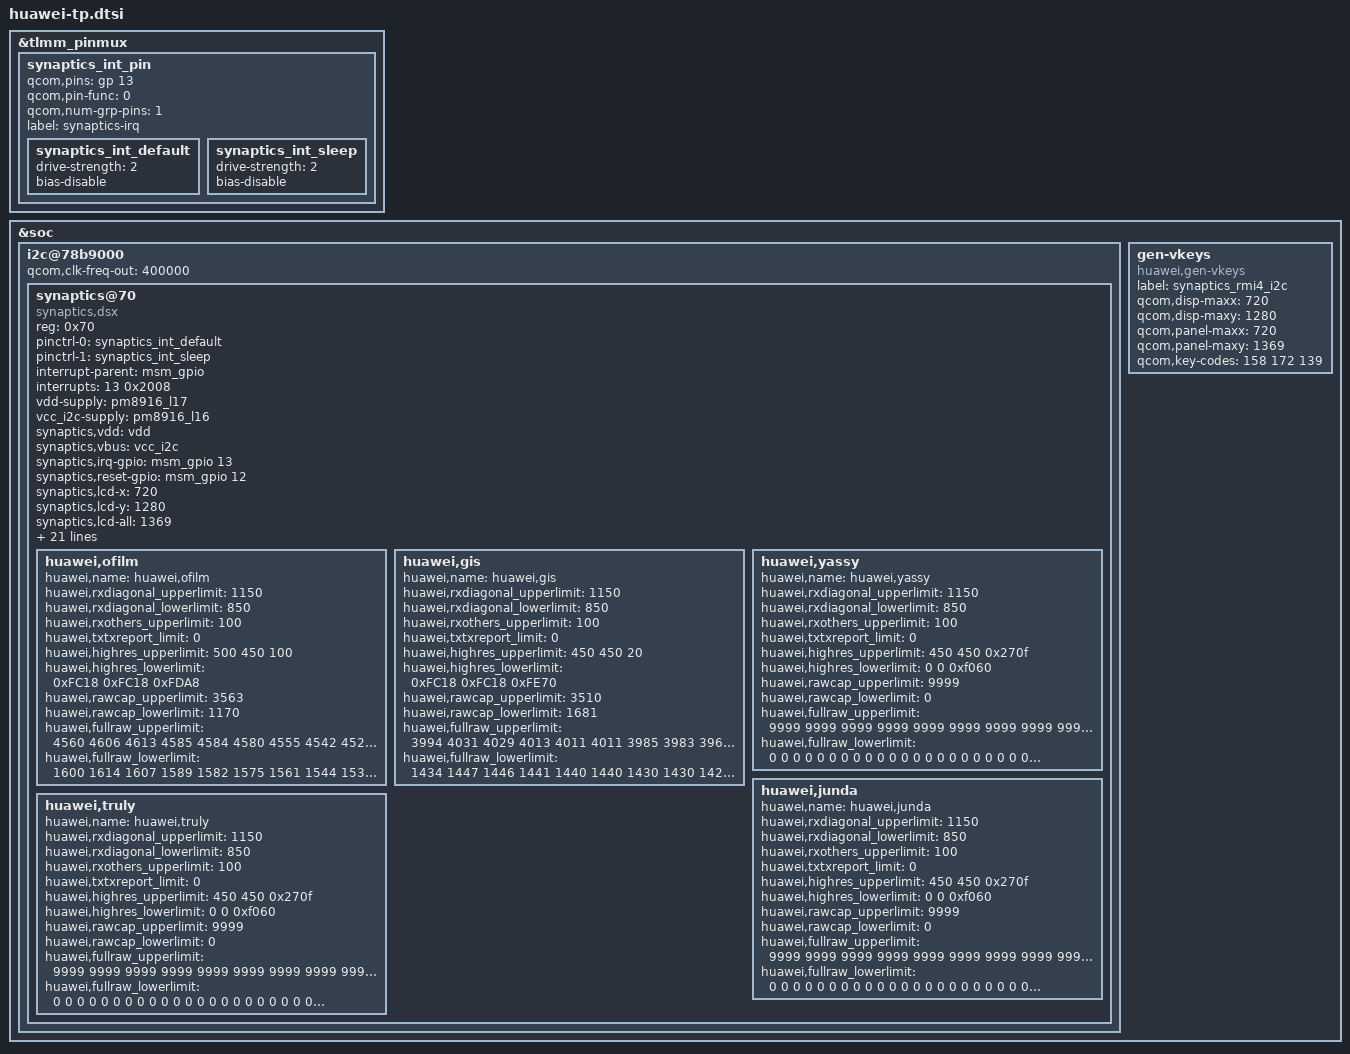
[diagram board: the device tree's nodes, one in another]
/*Add synaptics new driver "Synaptics DSX I2C V2.0"*/
/* Open holster flag */
&tlmm_pinmux {

	synaptics_int_pin {
		qcom,pins = <&gp 13>;
		qcom,pin-func = <0>;
		qcom,num-grp-pins = <1>;
		label = "synaptics-irq";
		synaptics_int_default: synaptics_int_default {
			drive-strength = <2>;
			bias-disable;
		};
		synaptics_int_sleep: synaptics_int_sleep {
			drive-strength = <2>;
			bias-disable;
		};
	};
};
&soc {
	i2c@78b9000 { /* BLSP1 QUP5 */
		status = "ok";
		#address-cells = <1>;
		#size-cells = <0>;
		qcom,clk-freq-out = <400000>;
		synaptics@70 {
			compatible = "synaptics,dsx";
			reg = <0x70>;
			pinctrl-names = "active","sleep";
			pinctrl-0 = <&synaptics_int_default>;
			pinctrl-1 = <&synaptics_int_sleep>;
			interrupt-parent = <&msm_gpio>;
			interrupts = <13 0x2008>;
			vdd-supply = <&pm8916_l17>;
			vcc_i2c-supply = <&pm8916_l16>;
			/* Some of qcom's param will not be replaced by huawei in dtb, */
			/* just ignore them:such as "pinctrl-names","pinctrl-0","pinctrl-1", */
			/* "synaptics,display-coords","synaptics,panel-coords","synaptics,i2c-pull-up", */
			/* "synaptics,power-down","synaptics,disable-gpios"*/
			synaptics,vdd = "vdd";
			synaptics,vbus = "vcc_i2c";
			synaptics,irq-gpio = <&msm_gpio 13 0x2008>;
			synaptics,reset-gpio = <&msm_gpio 12 0x0>;

			synaptics,lcd-x = <720>;
			synaptics,lcd-y = <1280>;
			synaptics,lcd-all = <1369>;
			synaptics,virtual_keys = /* KeyCode CenterX CenterY Width Height */
				/* KEY_BACK */
				<158 142 1342 150 100
				/* KEY_HOME(172) */
				172 360 1342 150 100
				/* KEY_MENU */
				139 578 1342 150 100>;

			/* SYNAPTICS_WAKE_UP_GESTURE_FLAG:'1'->enabled,'0'->disabled */
			/*IC flash is not enough for holster,so fw del one gesture*/
			synaptics,gesture_enabled = <0>;
			/* Gestures that supported:                           */
			/* bit0  Double tap                                        */
			/* bit1  Single finger slide from left to right     */
			/* bit2  Single finger slide from right to left     */
			/* bit3  Single finger slide from top to bottom  */
			/* bit4  Single finger slide from bottom to top  */
			/* bit5  Double finger slide from top to bottom--disable for holster*/
			/* bit6  Single finger slide circle                     */
			/* bit7  Single finger write letter c                  */
			/* bit8  Single finger write letter e                  */
			/* bit9  Single finger write letter m                 */
			/* bit10 Single finger write letter w                 */
			/* bit11 Palm off screen                                */
			synaptics,easy_wakeup_supported_gestures = <0xF81>;

			/*Defination of report key value  for different gestures*/
			synaptics,easy_wakeup_gesture_keys = 
			<	59 /*0.Double tap:KEY_F1*/
				60 /*1.Single finger slide from left to right*/
				61 /*2.Single finger slide from right to left:KEY_F3*/
				62 /*3.Single finger slide from top to bottom*/
				63 /*4.Single finger slide from bottom to top:KEY_F5*/
				64 /*5.Single finger slide circle clockwise*/
				65 /*6.Single finger slide circle counter-clockwise*/
				66 /*7.Single finger write letter c*/
				67 /*8.Single finger write letter e:KEY_F9*/
				68 /*9.Single finger write letter m*/
				87 /*10.Single finger write letter w:KEY_F11*/
				88 /*11.Palm off screen*/
			>;

			/* Double-tap-zone defined by huawei */
			/* Shielded area is:1cm left,1cm right,3cm up,2cm down */
			huawei,dtz_x0 = <104>;
			huawei,dtz_y0 = <423>;
			huawei,dtz_x1 = <616>;
			huawei,dtz_y1 = <1068>;

			/* SYNAPTICS_GLOVE_FUNCTION_FLAG:'1'->enabled,'0'->disabled*/
			synaptics,glove_enabled = <0>;
			/*After reduce power-consumption by exit reduce mode,*/
			/*we have to reduce f-r rate to make sure gesture work fine*/
			synaptics,fast_relax_gesture = <7>;
			/*Holster support flag*/
			synaptics,holster_supported = <1>;
			synaptics,esd_support = <1>;
			sybaptics,support_low_power_model = <0>;

			synaptics,reset-on-status = <0>;
			synaptics,power-delay-ms = <160>;
			synaptics,reset-delay-ms = <250>;
			synaptics,reset-active-ms = <10>;
			synaptics,product_name = "cherry";

			/*capacitance self-adapt*/
			/*To adjust the cutting angle threshold to the maximum range*/
			huawei,ofilm {
				huawei,name = "huawei,ofilm";
				huawei,rxdiagonal_upperlimit = <1150>;
				huawei,rxdiagonal_lowerlimit = <850>;
				huawei,rxothers_upperlimit = <100>;
				huawei,txtxreport_limit = <0>;
				huawei,highres_upperlimit = <500 450 100>;
				huawei,highres_lowerlimit = <0xFC18 0xFC18 0xFDA8>;
				huawei,rawcap_upperlimit = <3563>;
				huawei,rawcap_lowerlimit = <1170>;

				huawei,fullraw_upperlimit =
					<4560 4606 4613 4585 4584 4580 4555 4542 4527 4508 4491 4475 4448 4055 4026 4044 3985 4007 3958 3982 3931 3956 3907 3934 3791 3651
					 4416 4460 4442 4425 4404 4390 4374 4358 4342 4323 4308 4294 4263 4077 4044 4065 4011 4030 3986 4012 3964 3988 3941 3969 3827 3686
					 4402 4446 4425 4406 4386 4367 4349 4330 4312 4289 4274 4254 4225 4079 4051 4069 4015 4032 3991 4020 3969 3995 3948 3977 3838 3695
					 4398 4439 4420 4400 4376 4356 4336 4316 4297 4270 4255 4237 4207 4092 4066 4086 4032 4047 4005 4038 3986 4013 3968 3996 3857 3710
					 4380 4422 4399 4379 4355 4334 4312 4296 4271 4246 4228 4209 4178 4098 4075 4091 4042 4055 4016 4045 3994 4020 3979 4006 3868 3697
					 4368 4410 4384 4368 4341 4319 4294 4275 4254 4228 4211 4189 4155 4113 4089 4108 4059 4075 4032 4062 4016 4038 3998 4025 3888 3714
					 4362 4406 4381 4363 4335 4314 4289 4268 4248 4216 4203 4179 4143 4138 4110 4131 4086 4101 4060 4089 4046 4068 4028 4053 3919 3738
					 4353 4392 4370 4349 4323 4301 4277 4254 4231 4199 4185 4164 4127 4160 4134 4153 4108 4124 4080 4111 4070 4093 4052 4082 3944 3766
					 4337 4378 4353 4331 4307 4286 4260 4236 4216 4180 4167 4148 4107 4178 4155 4173 4129 4148 4103 4138 4094 4120 4081 4109 3968 3787
					 4337 4378 4351 4329 4301 4283 4255 4234 4212 4179 4165 4144 4105 4211 4190 4209 4165 4187 4145 4173 4131 4160 4123 4151 4011 3826
					 4325 4365 4339 4319 4292 4273 4246 4224 4201 4171 4155 4134 4092 4237 4218 4236 4199 4218 4181 4205 4167 4196 4162 4189 4046 3887
					 4320 4356 4335 4313 4286 4266 4241 4219 4193 4167 4151 4130 4087 4270 4251 4272 4237 4255 4220 4241 4211 4234 4202 4228 4086 3928
					 4321 4362 4336 4311 4288 4268 4244 4222 4198 4169 4153 4134 4090 4319 4302 4325 4291 4313 4283 4303 4272 4299 4263 4288 4148 3998
					 4314 4340 4316 4292 4265 4245 4218 4197 4168 4137 4120 4101 4051 4631 4590 4605 4541 4564 4538 4532 4507 4525 4483 4503 4357 4211>;

				huawei,fullraw_lowerlimit =
					<1600 1614 1607 1589 1582 1575 1561 1544 1530 1521 1509 1490 1479 1325 1301 1299 1283 1268 1230 1253 1238 1242 1218 1185 1180 1177 
					1555 1564 1551 1538 1525 1509 1501 1484 1470 1460 1449 1432 1423 1339 1316 1316 1267 1214 1213 1280 1256 1262 1218 1169 1191 1184 
					1548 1555 1544 1529 1518 1500 1491 1474 1458 1448 1435 1418 1405 1341 1318 1318 1214 1198 1174 1279 1261 1266 1240 1204 1224 1254 
					1543 1551 1533 1520 1509 1496 1484 1467 1453 1440 1421 1411 1397 1346 1325 1286 1198 1202 1178 1288 1264 1272 1250 1211 1252 1250 
					1536 1543 1530 1516 1502 1488 1478 1460 1444 1432 1416 1404 1389 1353 1333 1294 1208 1210 1231 1292 1275 1282 1257 1215 1262 1242 
					1533 1539 1526 1510 1496 1484 1471 1455 1439 1426 1411 1397 1378 1356 1337 1339 1299 1305 1288 1296 1278 1285 1264 1225 1267 1253 
					1527 1539 1519 1504 1490 1477 1465 1446 1429 1416 1400 1386 1365 1362 1341 1346 1321 1325 1297 1300 1283 1292 1269 1229 1273 1311 
					1524 1533 1517 1500 1484 1472 1460 1439 1425 1410 1395 1375 1355 1369 1348 1353 1327 1332 1306 1305 1292 1299 1281 1241 1279 1314 
					1519 1528 1512 1494 1478 1469 1451 1432 1420 1402 1387 1374 1354 1379 1361 1364 1342 1345 1316 1320 1302 1313 1291 1254 1293 1281 
					1519 1529 1512 1495 1480 1465 1450 1430 1415 1400 1383 1363 1344 1388 1369 1372 1348 1352 1328 1327 1314 1325 1304 1264 1299 1283 
					1514 1523 1505 1489 1475 1461 1447 1427 1411 1394 1378 1362 1341 1400 1379 1383 1360 1363 1341 1341 1323 1298 1288 1274 1310 1311 
					1512 1520 1503 1487 1471 1458 1443 1422 1407 1390 1375 1357 1334 1407 1388 1392 1370 1370 1350 1350 1291 1222 1213 1295 1320 1389 
					1511 1521 1503 1488 1471 1458 1441 1423 1404 1390 1371 1353 1328 1423 1400 1409 1386 1384 1367 1368 1304 1236 1225 1274 1336 1337 
					1516 1518 1502 1482 1464 1451 1432 1410 1395 1378 1358 1338 1313 1508 1490 1491 1457 1461 1433 1433 1418 1319 1290 1338 1379 1388>;
			};
			huawei,gis {
				huawei,name = "huawei,gis";
				huawei,rxdiagonal_upperlimit = <1150>;
				huawei,rxdiagonal_lowerlimit = <850>;
				huawei,rxothers_upperlimit = <100>;
				huawei,txtxreport_limit = <0>;
				huawei,highres_upperlimit = <450 450 20>;
				huawei,highres_lowerlimit = <0xFC18 0xFC18 0xFE70>;
				huawei,rawcap_upperlimit = <3510>;
				huawei,rawcap_lowerlimit = <1681>;

				huawei,fullraw_upperlimit =
					<3994 4031 4029 4013 4011 4011 3985 3983 3966 3957 3947 3942 4048 3531 3533 3520 3505 3494 3510 3487 3487 3472 3468 3450 3445 3279
					 4118 4151 4141 4118 4109 4105 4073 4068 4047 4034 4018 4011 3975 3790 3792 3778 3764 3754 3774 3751 3751 3738 3735 3715 3712 3583
					 4109 4141 4128 4104 4094 4087 4053 4050 4024 4011 3994 3982 3934 3790 3790 3775 3760 3753 3770 3748 3748 3735 3732 3713 3715 3868
					 4096 4130 4116 4091 4078 4072 4037 4030 4004 3988 3972 3962 3908 3797 3796 3783 3770 3761 3780 3757 3758 3744 3740 3723 3721 3645
					 4077 4116 4100 4076 4064 4056 4021 4013 3986 3972 3953 3946 3887 3808 3805 3792 3782 3773 3792 3770 3770 3757 3753 3734 3731 3565
					 4069 4107 4092 4068 4055 4047 4011 4003 3974 3959 3942 3931 3870 3823 3821 3808 3796 3788 3808 3784 3784 3771 3767 3751 3747 3595
					 4061 4098 4081 4056 4042 4034 3996 3988 3960 3944 3926 3916 3852 3840 3835 3822 3809 3803 3822 3799 3799 3784 3780 3764 3766 3862
					 4052 4087 4070 4044 4030 4024 3985 3977 3947 3933 3914 3904 3839 3865 3857 3844 3831 3823 3843 3819 3819 3805 3804 3783 3787 3866
					 4046 4079 4064 4038 4022 4016 3979 3969 3940 3926 3908 3899 3831 3888 3878 3866 3856 3847 3868 3847 3847 3834 3831 3813 3813 3676
					 4042 4077 4060 4034 4018 4011 3974 3965 3938 3923 3904 3894 3825 3917 3905 3895 3882 3874 3895 3873 3873 3861 3860 3843 3844 3708
					 4038 4073 4056 4029 4014 4005 3968 3960 3931 3918 3897 3887 3819 3946 3930 3921 3909 3900 3921 3900 3900 3888 3887 3874 3877 3826
					 4034 4070 4052 4026 4011 4003 3965 3959 3927 3914 3895 3886 3816 3973 3957 3947 3936 3927 3947 3926 3927 3917 3921 3907 3916 4157
					 4029 4065 4050 4024 4011 4003 3968 3960 3931 3918 3900 3891 3821 4029 4001 3992 3983 3973 3995 3977 3978 3970 3974 3961 3964 3905
					 3797 3821 3804 3777 3762 3752 3715 3705 3675 3662 3643 3632 3562 4563 4117 4079 4051 4031 4043 4018 4014 4004 4003 3990 3994 4120>;

				huawei,fullraw_lowerlimit =
					<1434 1447 1446 1441 1440 1440 1430 1430 1424 1420 1417 1415 1453 1268 1268 1264 1258 1254 1260 1252 1252 1247 1245 1239 1237 1177
					 1478 1490 1486 1478 1475 1474 1462 1460 1453 1448 1443 1440 1427 1360 1362 1356 1351 1348 1355 1346 1346 1342 1341 1334 1332 1286
					 1476 1486 1482 1474 1469 1467 1455 1453 1444 1439 1434 1429 1413 1360 1360 1355 1350 1347 1354 1345 1345 1341 1340 1333 1334 1280
					 1471 1483 1478 1469 1464 1462 1449 1447 1437 1432 1426 1422 1403 1363 1363 1358 1353 1350 1357 1349 1349 1344 1343 1337 1336 1308
					 1464 1477 1472 1463 1459 1456 1443 1441 1431 1426 1419 1416 1395 1367 1366 1362 1357 1354 1362 1353 1353 1349 1347 1341 1340 1280
					 1460 1474 1469 1460 1455 1453 1439 1436 1427 1421 1415 1411 1389 1373 1371 1367 1363 1359 1367 1359 1359 1354 1352 1346 1345 1290
					 1457 1471 1465 1456 1451 1448 1434 1432 1421 1416 1409 1406 1383 1379 1376 1372 1367 1365 1372 1364 1364 1359 1357 1351 1352 1386
					 1455 1467 1462 1452 1447 1444 1431 1427 1417 1412 1406 1401 1378 1387 1385 1380 1376 1372 1380 1371 1371 1366 1366 1358 1359 1387
					 1452 1464 1459 1450 1444 1441 1428 1425 1415 1409 1403 1399 1375 1396 1392 1388 1384 1381 1389 1381 1381 1376 1376 1369 1369 1320
					 1451 1463 1457 1448 1443 1440 1427 1423 1413 1408 1401 1398 1373 1406 1402 1398 1394 1390 1399 1390 1390 1386 1386 1380 1380 1331
					 1449 1462 1456 1446 1441 1438 1425 1422 1411 1406 1399 1396 1371 1416 1411 1408 1403 1400 1408 1400 1400 1396 1395 1390 1392 1373
					 1448 1461 1455 1446 1440 1437 1423 1421 1410 1405 1398 1395 1370 1427 1420 1417 1413 1410 1417 1409 1410 1406 1408 1402 1406 1492
					 1446 1460 1454 1444 1440 1437 1425 1422 1411 1406 1400 1397 1371 1446 1436 1433 1430 1427 1434 1427 1428 1425 1427 1422 1423 1402
					 1363 1372 1365 1356 1350 1347 1334 1330 1320 1315 1308 1304 1279 1638 1478 1464 1454 1447 1452 1442 1441 1437 1436 1432 1434 1479>;
			};
			huawei,yassy {
				huawei,name = "huawei,yassy";
				huawei,rxdiagonal_upperlimit = <1150>;
				huawei,rxdiagonal_lowerlimit = <850>;
				huawei,rxothers_upperlimit = <100>;
				huawei,txtxreport_limit = <0>;
				huawei,highres_upperlimit = <450 450 0x270f>;/*0x270f==9999*/
				huawei,highres_lowerlimit = <0 0 0xf060>;/*0xf060==-4000*/
				huawei,rawcap_upperlimit = <9999>;
				huawei,rawcap_lowerlimit = <0>;

				huawei,fullraw_upperlimit =
					<9999 9999 9999 9999 9999 9999 9999 9999 9999 9999 9999 9999 9999 9999 9999 9999 9999 9999 9999 9999 9999 9999 9999 9999 
					9999 9999 9999 9999 9999 9999 9999 9999 9999 9999 9999 9999 9999 9999 9999 9999 9999 9999 9999 9999 9999 9999 9999 9999 
					9999 9999 9999 9999 9999 9999 9999 9999 9999 9999 9999 9999 9999 9999 9999 9999 9999 9999 9999 9999 9999 9999 9999 9999 
					9999 9999 9999 9999 9999 9999 9999 9999 9999 9999 9999 9999 9999 9999 9999 9999 9999 9999 9999 9999 9999 9999 9999 9999 
					9999 9999 9999 9999 9999 9999 9999 9999 9999 9999 9999 9999 9999 9999 9999 9999 9999 9999 9999 9999 9999 9999 9999 9999 
					9999 9999 9999 9999 9999 9999 9999 9999 9999 9999 9999 9999 9999 9999 9999 9999 9999 9999 9999 9999 9999 9999 9999 9999 
					9999 9999 9999 9999 9999 9999 9999 9999 9999 9999 9999 9999 9999 9999 9999 9999 9999 9999 9999 9999 9999 9999 9999 9999 
					9999 9999 9999 9999 9999 9999 9999 9999 9999 9999 9999 9999 9999 9999 9999 9999 9999 9999 9999 9999 9999 9999 9999 9999 
					9999 9999 9999 9999 9999 9999 9999 9999 9999 9999 9999 9999 9999 9999 9999 9999 9999 9999 9999 9999 9999 9999 9999 9999 
					9999 9999 9999 9999 9999 9999 9999 9999 9999 9999 9999 9999 9999 9999 9999 9999 9999 9999 9999 9999 9999 9999 9999 9999 
					9999 9999 9999 9999 9999 9999 9999 9999 9999 9999 9999 9999 9999 9999 9999 9999 9999 9999 9999 9999 9999 9999 9999 9999 
					9999 9999 9999 9999 9999 9999 9999 9999 9999 9999 9999 9999 9999 9999 9999 9999 9999 9999 9999 9999 9999 9999 9999 9999 
					9999 9999 9999 9999 9999 9999 9999 9999 9999 9999 9999 9999 9999 9999 9999 9999 9999 9999 9999 9999 9999 9999 9999 9999>;

				huawei,fullraw_lowerlimit =
					<0 0 0 0 0 0 0 0 0 0 0 0 0 0 0 0 0 0 0 0 0 0 0 0 
					0 0 0 0 0 0 0 0 0 0 0 0 0 0 0 0 0 0 0 0 0 0 0 0 
					0 0 0 0 0 0 0 0 0 0 0 0 0 0 0 0 0 0 0 0 0 0 0 0 
					0 0 0 0 0 0 0 0 0 0 0 0 0 0 0 0 0 0 0 0 0 0 0 0 
					0 0 0 0 0 0 0 0 0 0 0 0 0 0 0 0 0 0 0 0 0 0 0 0 
					0 0 0 0 0 0 0 0 0 0 0 0 0 0 0 0 0 0 0 0 0 0 0 0 
					0 0 0 0 0 0 0 0 0 0 0 0 0 0 0 0 0 0 0 0 0 0 0 0 
					0 0 0 0 0 0 0 0 0 0 0 0 0 0 0 0 0 0 0 0 0 0 0 0 
					0 0 0 0 0 0 0 0 0 0 0 0 0 0 0 0 0 0 0 0 0 0 0 0 
					0 0 0 0 0 0 0 0 0 0 0 0 0 0 0 0 0 0 0 0 0 0 0 0  
					0 0 0 0 0 0 0 0 0 0 0 0 0 0 0 0 0 0 0 0 0 0 0 0 
					0 0 0 0 0 0 0 0 0 0 0 0 0 0 0 0 0 0 0 0 0 0 0 0 
					0 0 0 0 0 0 0 0 0 0 0 0 0 0 0 0 0 0 0 0 0 0 0 0>;
			};
			huawei,junda {
				huawei,name = "huawei,junda";
				huawei,rxdiagonal_upperlimit = <1150>;
				huawei,rxdiagonal_lowerlimit = <850>;
				huawei,rxothers_upperlimit = <100>;
				huawei,txtxreport_limit = <0>;
				huawei,highres_upperlimit = <450 450 0x270f>;/*0x270f==9999*/
				huawei,highres_lowerlimit = <0 0 0xf060>;/*0xf060==-4000*/
				huawei,rawcap_upperlimit = <9999>;
				huawei,rawcap_lowerlimit = <0>;

				huawei,fullraw_upperlimit =
					<9999 9999 9999 9999 9999 9999 9999 9999 9999 9999 9999 9999 9999 9999 9999 9999 9999 9999 9999 9999 9999 9999 9999 9999 
					9999 9999 9999 9999 9999 9999 9999 9999 9999 9999 9999 9999 9999 9999 9999 9999 9999 9999 9999 9999 9999 9999 9999 9999 
					9999 9999 9999 9999 9999 9999 9999 9999 9999 9999 9999 9999 9999 9999 9999 9999 9999 9999 9999 9999 9999 9999 9999 9999 
					9999 9999 9999 9999 9999 9999 9999 9999 9999 9999 9999 9999 9999 9999 9999 9999 9999 9999 9999 9999 9999 9999 9999 9999 
					9999 9999 9999 9999 9999 9999 9999 9999 9999 9999 9999 9999 9999 9999 9999 9999 9999 9999 9999 9999 9999 9999 9999 9999 
					9999 9999 9999 9999 9999 9999 9999 9999 9999 9999 9999 9999 9999 9999 9999 9999 9999 9999 9999 9999 9999 9999 9999 9999 
					9999 9999 9999 9999 9999 9999 9999 9999 9999 9999 9999 9999 9999 9999 9999 9999 9999 9999 9999 9999 9999 9999 9999 9999 
					9999 9999 9999 9999 9999 9999 9999 9999 9999 9999 9999 9999 9999 9999 9999 9999 9999 9999 9999 9999 9999 9999 9999 9999 
					9999 9999 9999 9999 9999 9999 9999 9999 9999 9999 9999 9999 9999 9999 9999 9999 9999 9999 9999 9999 9999 9999 9999 9999 
					9999 9999 9999 9999 9999 9999 9999 9999 9999 9999 9999 9999 9999 9999 9999 9999 9999 9999 9999 9999 9999 9999 9999 9999 
					9999 9999 9999 9999 9999 9999 9999 9999 9999 9999 9999 9999 9999 9999 9999 9999 9999 9999 9999 9999 9999 9999 9999 9999 
					9999 9999 9999 9999 9999 9999 9999 9999 9999 9999 9999 9999 9999 9999 9999 9999 9999 9999 9999 9999 9999 9999 9999 9999 
					9999 9999 9999 9999 9999 9999 9999 9999 9999 9999 9999 9999 9999 9999 9999 9999 9999 9999 9999 9999 9999 9999 9999 9999>;

				huawei,fullraw_lowerlimit =
					<0 0 0 0 0 0 0 0 0 0 0 0 0 0 0 0 0 0 0 0 0 0 0 0 
					0 0 0 0 0 0 0 0 0 0 0 0 0 0 0 0 0 0 0 0 0 0 0 0 
					0 0 0 0 0 0 0 0 0 0 0 0 0 0 0 0 0 0 0 0 0 0 0 0 
					0 0 0 0 0 0 0 0 0 0 0 0 0 0 0 0 0 0 0 0 0 0 0 0 
					0 0 0 0 0 0 0 0 0 0 0 0 0 0 0 0 0 0 0 0 0 0 0 0 
					0 0 0 0 0 0 0 0 0 0 0 0 0 0 0 0 0 0 0 0 0 0 0 0 
					0 0 0 0 0 0 0 0 0 0 0 0 0 0 0 0 0 0 0 0 0 0 0 0 
					0 0 0 0 0 0 0 0 0 0 0 0 0 0 0 0 0 0 0 0 0 0 0 0 
					0 0 0 0 0 0 0 0 0 0 0 0 0 0 0 0 0 0 0 0 0 0 0 0 
					0 0 0 0 0 0 0 0 0 0 0 0 0 0 0 0 0 0 0 0 0 0 0 0  
					0 0 0 0 0 0 0 0 0 0 0 0 0 0 0 0 0 0 0 0 0 0 0 0 
					0 0 0 0 0 0 0 0 0 0 0 0 0 0 0 0 0 0 0 0 0 0 0 0 
					0 0 0 0 0 0 0 0 0 0 0 0 0 0 0 0 0 0 0 0 0 0 0 0>;
			};
			huawei,truly {
				huawei,name = "huawei,truly";
				huawei,rxdiagonal_upperlimit = <1150>;
				huawei,rxdiagonal_lowerlimit = <850>;
				huawei,rxothers_upperlimit = <100>;
				huawei,txtxreport_limit = <0>;
				huawei,highres_upperlimit = <450 450 0x270f>;/*0x270f==9999*/
				huawei,highres_lowerlimit = <0 0 0xf060>;/*0xf060==-4000*/
				huawei,rawcap_upperlimit = <9999>;
				huawei,rawcap_lowerlimit = <0>;

				huawei,fullraw_upperlimit =
					<9999 9999 9999 9999 9999 9999 9999 9999 9999 9999 9999 9999 9999 9999 9999 9999 9999 9999 9999 9999 9999 9999 9999 9999 
					9999 9999 9999 9999 9999 9999 9999 9999 9999 9999 9999 9999 9999 9999 9999 9999 9999 9999 9999 9999 9999 9999 9999 9999 
					9999 9999 9999 9999 9999 9999 9999 9999 9999 9999 9999 9999 9999 9999 9999 9999 9999 9999 9999 9999 9999 9999 9999 9999 
					9999 9999 9999 9999 9999 9999 9999 9999 9999 9999 9999 9999 9999 9999 9999 9999 9999 9999 9999 9999 9999 9999 9999 9999 
					9999 9999 9999 9999 9999 9999 9999 9999 9999 9999 9999 9999 9999 9999 9999 9999 9999 9999 9999 9999 9999 9999 9999 9999 
					9999 9999 9999 9999 9999 9999 9999 9999 9999 9999 9999 9999 9999 9999 9999 9999 9999 9999 9999 9999 9999 9999 9999 9999 
					9999 9999 9999 9999 9999 9999 9999 9999 9999 9999 9999 9999 9999 9999 9999 9999 9999 9999 9999 9999 9999 9999 9999 9999 
					9999 9999 9999 9999 9999 9999 9999 9999 9999 9999 9999 9999 9999 9999 9999 9999 9999 9999 9999 9999 9999 9999 9999 9999 
					9999 9999 9999 9999 9999 9999 9999 9999 9999 9999 9999 9999 9999 9999 9999 9999 9999 9999 9999 9999 9999 9999 9999 9999 
					9999 9999 9999 9999 9999 9999 9999 9999 9999 9999 9999 9999 9999 9999 9999 9999 9999 9999 9999 9999 9999 9999 9999 9999 
					9999 9999 9999 9999 9999 9999 9999 9999 9999 9999 9999 9999 9999 9999 9999 9999 9999 9999 9999 9999 9999 9999 9999 9999 
					9999 9999 9999 9999 9999 9999 9999 9999 9999 9999 9999 9999 9999 9999 9999 9999 9999 9999 9999 9999 9999 9999 9999 9999 
					9999 9999 9999 9999 9999 9999 9999 9999 9999 9999 9999 9999 9999 9999 9999 9999 9999 9999 9999 9999 9999 9999 9999 9999>;

				huawei,fullraw_lowerlimit =
					<0 0 0 0 0 0 0 0 0 0 0 0 0 0 0 0 0 0 0 0 0 0 0 0 
					0 0 0 0 0 0 0 0 0 0 0 0 0 0 0 0 0 0 0 0 0 0 0 0 
					0 0 0 0 0 0 0 0 0 0 0 0 0 0 0 0 0 0 0 0 0 0 0 0 
					0 0 0 0 0 0 0 0 0 0 0 0 0 0 0 0 0 0 0 0 0 0 0 0 
					0 0 0 0 0 0 0 0 0 0 0 0 0 0 0 0 0 0 0 0 0 0 0 0 
					0 0 0 0 0 0 0 0 0 0 0 0 0 0 0 0 0 0 0 0 0 0 0 0 
					0 0 0 0 0 0 0 0 0 0 0 0 0 0 0 0 0 0 0 0 0 0 0 0 
					0 0 0 0 0 0 0 0 0 0 0 0 0 0 0 0 0 0 0 0 0 0 0 0 
					0 0 0 0 0 0 0 0 0 0 0 0 0 0 0 0 0 0 0 0 0 0 0 0 
					0 0 0 0 0 0 0 0 0 0 0 0 0 0 0 0 0 0 0 0 0 0 0 0  
					0 0 0 0 0 0 0 0 0 0 0 0 0 0 0 0 0 0 0 0 0 0 0 0 
					0 0 0 0 0 0 0 0 0 0 0 0 0 0 0 0 0 0 0 0 0 0 0 0 
					0 0 0 0 0 0 0 0 0 0 0 0 0 0 0 0 0 0 0 0 0 0 0 0>;
			};
		};
	};
	
	/*To disable gen-vkeys.c probe,avoid generate kobject*/
	gen-vkeys {
		compatible = "huawei,gen-vkeys";
		label = "synaptics_rmi4_i2c";
		qcom,disp-maxx = <720>;
		qcom,disp-maxy = <1280>;
		qcom,panel-maxx = <720>;
		qcom,panel-maxy = <1369>;
		qcom,key-codes = <158 172 139>;
	};

};
